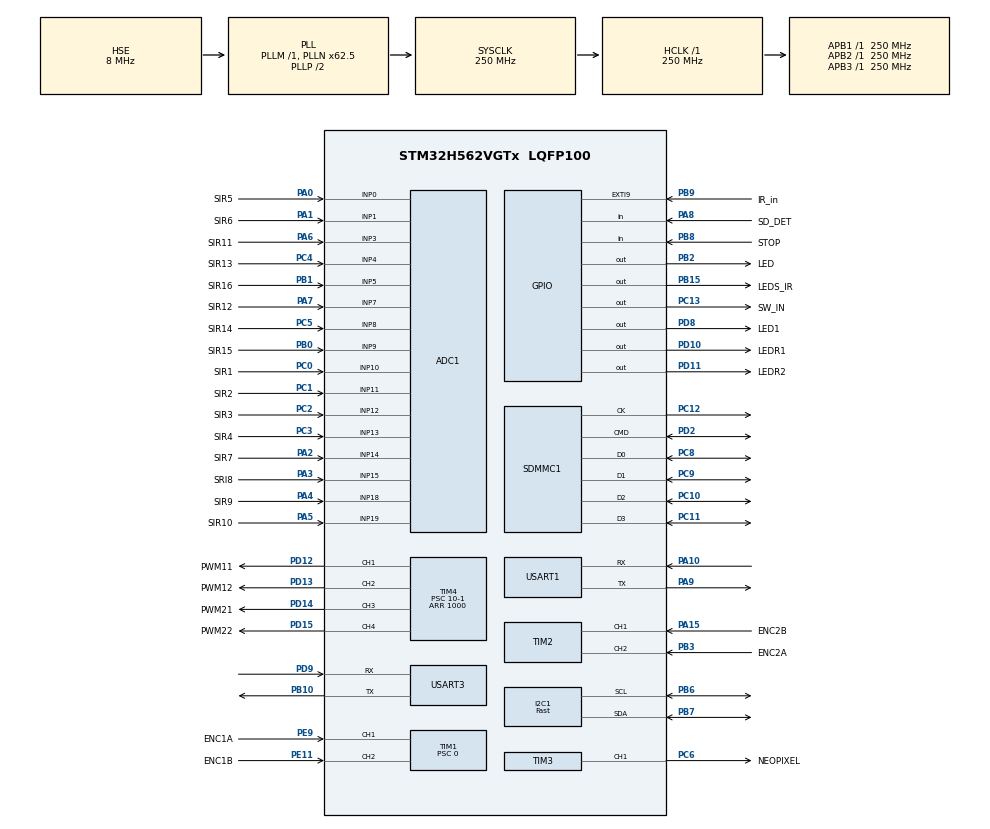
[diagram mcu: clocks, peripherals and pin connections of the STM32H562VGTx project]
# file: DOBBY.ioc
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ADC1.Channel-0\#ChannelRegularConversion=ADC_CHANNEL_10
ADC1.Channel-1\#ChannelRegularConversion=ADC_CHANNEL_11
ADC1.Channel-10\#ChannelRegularConversion=ADC_CHANNEL_3
ADC1.Channel-11\#ChannelRegularConversion=ADC_CHANNEL_7
ADC1.Channel-12\#ChannelRegularConversion=ADC_CHANNEL_4
ADC1.Channel-13\#ChannelRegularConversion=ADC_CHANNEL_8
ADC1.Channel-14\#ChannelRegularConversion=ADC_CHANNEL_9
ADC1.Channel-15\#ChannelRegularConversion=ADC_CHANNEL_5
ADC1.Channel-2\#ChannelRegularConversion=ADC_CHANNEL_12
ADC1.Channel-3\#ChannelRegularConversion=ADC_CHANNEL_13
ADC1.Channel-4\#ChannelRegularConversion=ADC_CHANNEL_0
ADC1.Channel-5\#ChannelRegularConversion=ADC_CHANNEL_1
ADC1.Channel-6\#ChannelRegularConversion=ADC_CHANNEL_15
ADC1.Channel-7\#ChannelRegularConversion=ADC_CHANNEL_14
ADC1.Channel-8\#ChannelRegularConversion=ADC_CHANNEL_18
ADC1.Channel-9\#ChannelRegularConversion=ADC_CHANNEL_19
ADC1.ClockPrescaler=ADC_CLOCK_ASYNC_DIV4
ADC1.ContinuousConvMode=ENABLE
ADC1.ConversionDataManagement=ADC_CONVERSIONDATA_DMA_CIRCULAR
ADC1.DMAContinuousRequests=ENABLE
ADC1.EOCSelection=ADC_EOC_SEQ_CONV
ADC1.MonitoredBy-0\#ChannelRegularConversion=__NULL
ADC1.MonitoredBy-1\#ChannelRegularConversion=__NULL
ADC1.MonitoredBy-10\#ChannelRegularConversion=__NULL
ADC1.MonitoredBy-11\#ChannelRegularConversion=__NULL
ADC1.MonitoredBy-12\#ChannelRegularConversion=__NULL
ADC1.MonitoredBy-13\#ChannelRegularConversion=__NULL
ADC1.MonitoredBy-14\#ChannelRegularConversion=__NULL
ADC1.MonitoredBy-15\#ChannelRegularConversion=__NULL
ADC1.MonitoredBy-2\#ChannelRegularConversion=__NULL
ADC1.MonitoredBy-3\#ChannelRegularConversion=__NULL
ADC1.MonitoredBy-4\#ChannelRegularConversion=__NULL
ADC1.MonitoredBy-5\#ChannelRegularConversion=__NULL
ADC1.MonitoredBy-6\#ChannelRegularConversion=__NULL
ADC1.MonitoredBy-7\#ChannelRegularConversion=__NULL
ADC1.MonitoredBy-8\#ChannelRegularConversion=__NULL
ADC1.MonitoredBy-9\#ChannelRegularConversion=__NULL
ADC1.NbrOfConversion=16
ADC1.NbrOfConversionFlag=1
ADC1.OffsetNumber-0\#ChannelRegularConversion=ADC_OFFSET_NONE
ADC1.OffsetNumber-1\#ChannelRegularConversion=ADC_OFFSET_NONE
ADC1.OffsetNumber-10\#ChannelRegularConversion=ADC_OFFSET_NONE
ADC1.OffsetNumber-11\#ChannelRegularConversion=ADC_OFFSET_NONE
ADC1.OffsetNumber-12\#ChannelRegularConversion=ADC_OFFSET_NONE
ADC1.OffsetNumber-13\#ChannelRegularConversion=ADC_OFFSET_NONE
ADC1.OffsetNumber-14\#ChannelRegularConversion=ADC_OFFSET_NONE
ADC1.OffsetNumber-15\#ChannelRegularConversion=ADC_OFFSET_NONE
ADC1.OffsetNumber-2\#ChannelRegularConversion=ADC_OFFSET_NONE
ADC1.OffsetNumber-3\#ChannelRegularConversion=ADC_OFFSET_NONE
ADC1.OffsetNumber-4\#ChannelRegularConversion=ADC_OFFSET_NONE
ADC1.OffsetNumber-5\#ChannelRegularConversion=ADC_OFFSET_NONE
ADC1.OffsetNumber-6\#ChannelRegularConversion=ADC_OFFSET_NONE
ADC1.OffsetNumber-7\#ChannelRegularConversion=ADC_OFFSET_NONE
ADC1.OffsetNumber-8\#ChannelRegularConversion=ADC_OFFSET_NONE
ADC1.OffsetNumber-9\#ChannelRegularConversion=ADC_OFFSET_NONE
ADC1.Rank-0\#ChannelRegularConversion=1
ADC1.Rank-1\#ChannelRegularConversion=2
ADC1.Rank-10\#ChannelRegularConversion=11
ADC1.Rank-11\#ChannelRegularConversion=12
ADC1.Rank-12\#ChannelRegularConversion=13
ADC1.Rank-13\#ChannelRegularConversion=14
ADC1.Rank-14\#ChannelRegularConversion=15
ADC1.Rank-15\#ChannelRegularConversion=16
ADC1.Rank-2\#ChannelRegularConversion=3
ADC1.Rank-3\#ChannelRegularConversion=4
ADC1.Rank-4\#ChannelRegularConversion=5
ADC1.Rank-5\#ChannelRegularConversion=6
ADC1.Rank-6\#ChannelRegularConversion=7
ADC1.Rank-7\#ChannelRegularConversion=8
ADC1.Rank-8\#ChannelRegularConversion=9
ADC1.Rank-9\#ChannelRegularConversion=10
ADC1.SamplingTime-0\#ChannelRegularConversion=ADC_SAMPLETIME_247CYCLES_5
ADC1.SamplingTime-1\#ChannelRegularConversion=ADC_SAMPLETIME_247CYCLES_5
ADC1.SamplingTime-10\#ChannelRegularConversion=ADC_SAMPLETIME_247CYCLES_5
ADC1.SamplingTime-11\#ChannelRegularConversion=ADC_SAMPLETIME_247CYCLES_5
ADC1.SamplingTime-12\#ChannelRegularConversion=ADC_SAMPLETIME_247CYCLES_5
ADC1.SamplingTime-13\#ChannelRegularConversion=ADC_SAMPLETIME_247CYCLES_5
ADC1.SamplingTime-14\#ChannelRegularConversion=ADC_SAMPLETIME_247CYCLES_5
ADC1.SamplingTime-15\#ChannelRegularConversion=ADC_SAMPLETIME_247CYCLES_5
ADC1.SamplingTime-2\#ChannelRegularConversion=ADC_SAMPLETIME_2CYCLES_5
ADC1.SamplingTime-3\#ChannelRegularConversion=ADC_SAMPLETIME_247CYCLES_5
ADC1.SamplingTime-4\#ChannelRegularConversion=ADC_SAMPLETIME_247CYCLES_5
ADC1.SamplingTime-5\#ChannelRegularConversion=ADC_SAMPLETIME_247CYCLES_5
ADC1.SamplingTime-6\#ChannelRegularConversion=ADC_SAMPLETIME_247CYCLES_5
ADC1.SamplingTime-7\#ChannelRegularConversion=ADC_SAMPLETIME_247CYCLES_5
ADC1.SamplingTime-8\#ChannelRegularConversion=ADC_SAMPLETIME_247CYCLES_5
ADC1.SamplingTime-9\#ChannelRegularConversion=ADC_SAMPLETIME_247CYCLES_5
ADC1.master=1
BOOTPATH.BootPathName=LEGACY
BOOTPATH.UserSelectedBootPath=LEGACY
CORTEX_M33_NS.Number-Cortex_Memory_Protection_Unit_Region0_OTP_RO_AREAS_Settings=MPU_REGION_NUMBER0
CORTEX_M33_NS.default_mode_Activation=1
CORTEX_M33_NS.userName=CORTEX_M33
GPDMA1.DESTDATAWIDTH_GPDMACH0=DMA_DEST_DATAWIDTH_BYTE
GPDMA1.DESTDATAWIDTH_GPDMACH1=DMA_DEST_DATAWIDTH_HALFWORD
GPDMA1.DESTINC_GPDMACH0=DMA_DINC_INCREMENTED
GPDMA1.DIRECTION_GPDMACH0=DMA_PERIPH_TO_MEMORY
GPDMA1.DIRECTION_GPDMACH1=DMA_MEMORY_TO_PERIPH
GPDMA1.IPHANDLE_GPDMACH0-SIMPLEREQUEST_GPDMACH0=__NULL
GPDMA1.IPHANDLE_GPDMACH1-SIMPLEREQUEST_GPDMACH1=__NULL
GPDMA1.PRIORITY_GPDMACH0=DMA_LOW_PRIORITY_HIGH_WEIGHT
GPDMA1.REQUEST_GPDMACH0=GPDMA1_REQUEST_USART1_RX
GPDMA1.REQUEST_GPDMACH1=GPDMA1_REQUEST_TIM3_CH1
GPDMA1.SRCDATAWIDTH_GPDMACH0=DMA_SRC_DATAWIDTH_BYTE
GPDMA1.SRCDATAWIDTH_GPDMACH1=DMA_SRC_DATAWIDTH_HALFWORD
GPDMA1.SRCINC_GPDMACH0=DMA_SINC_FIXED
GPDMA1.SRCINC_GPDMACH1=DMA_SINC_INCREMENTED
GPDMA2.CIRCULARMODE_GPDMACH0=ENABLE
GPDMA2.DESTDATAWIDTH_GPDMACH0=DMA_DEST_DATAWIDTH_HALFWORD
GPDMA2.DESTINC_GPDMACH0=DMA_DINC_INCREMENTED
GPDMA2.IPHANDLE_GPDMACH0-SIMPLEREQUEST_GPDMACH0=__NULL
GPDMA2.PRIORITY_LL_CIRCULAR_GPDMACH0=DMA_HIGH_PRIORITY
GPDMA2.REQUEST_GPDMACH0=GPDMA2_REQUEST_ADC1
GPDMA2.SRCDATAWIDTH_GPDMACH0=DMA_SRC_DATAWIDTH_HALFWORD
I2C1.I2C_Speed_Mode=I2C_Fast
I2C1.Timing=0x10C043E5
Mcu.Family=STM32H5
Mcu.Name=STM32H562VGTx
Mcu.Package=LQFP100
NVIC.EXTI9_IRQn=true\:0\:0\:true\:false\:true\:true\:true\:true
NVIC.GPDMA1_Channel0_IRQn=true\:0\:0\:false\:false\:true\:false\:true\:true
NVIC.GPDMA1_Channel1_IRQn=true\:0\:0\:false\:false\:true\:false\:true\:true
NVIC.GPDMA2_Channel0_IRQn=true\:0\:0\:false\:false\:true\:false\:true\:true
NVIC.PriorityGroup=NVIC_PRIORITYGROUP_4
NVIC.TIM6_IRQn=true\:1\:0\:true\:false\:true\:true\:true\:true
NVIC.TIM7_IRQn=true\:2\:0\:true\:false\:true\:true\:true\:true
NVIC.USART1_IRQn=true\:1\:0\:true\:false\:true\:true\:true\:true
PA0.GPIO_Label=SIR5
PA0.Signal=ADCx_INP0
PA1.GPIO_Label=SIR6
PA1.Signal=ADCx_INP1
PA10.Mode=Asynchronous
PA10.Signal=USART1_RX
PA15(JTDI).GPIO_Label=ENC2B
PA15(JTDI).Signal=S_TIM2_CH1
PA2.GPIO_Label=SIR7
PA2.Signal=ADCx_INP14
PA3.GPIO_Label=SRI8
PA3.Signal=ADCx_INP15
PA4.GPIO_Label=SIR9
PA4.Signal=ADCx_INP18
PA5.GPIO_Label=SIR10
PA5.Signal=ADCx_INP19
PA6.GPIO_Label=SIR11
PA6.Signal=ADCx_INP3
PA7.GPIO_Label=SIR12
PA7.Signal=ADCx_INP7
PA8.GPIO_Label=SD_DET
PA8.GPIO_PuPd=GPIO_PULLUP
PA8.Signal=GPIO_Input
PA9.Mode=Asynchronous
PA9.Signal=USART1_TX
PB0.GPIO_Label=SIR15
PB0.Signal=ADCx_INP9
PB1.GPIO_Label=SIR16
PB1.Signal=ADCx_INP5
PB10.Mode=Asynchronous
PB10.Signal=USART3_TX
PB15.GPIO_Label=LEDS_IR
PB15.Signal=GPIO_Output
PB2.GPIO_Label=LED
PB2.Signal=GPIO_Output
PB3(JTDO/TRACESWO).GPIO_Label=ENC2A
PB3(JTDO/TRACESWO).Signal=S_TIM2_CH2
PB6.Mode=I2C
PB6.Signal=I2C1_SCL
PB7.Mode=I2C
PB7.Signal=I2C1_SDA
PB8.GPIO_Label=STOP
PB8.Signal=GPIO_Input
PB9.GPIO_Label=IR_in
PB9.GPIO_PuPd=GPIO_PULLUP
PB9.Signal=GPXTI9
PC0.GPIO_Label=SIR1
PC0.Signal=ADCx_INP10
PC1.GPIO_Label=SIR2
PC1.Signal=ADCx_INP11
PC10.GPIO_Speed_Default_HIGH=GPIO_SPEED_FREQ_VERY_HIGH
PC10.Mode=SD_4_bits_Wide_bus
PC10.Signal=SDMMC1_D2
PC11.GPIO_Speed_Default_HIGH=GPIO_SPEED_FREQ_VERY_HIGH
PC11.Mode=SD_4_bits_Wide_bus
PC11.Signal=SDMMC1_D3
PC12.GPIO_Speed_Default_HIGH=GPIO_SPEED_FREQ_VERY_HIGH
PC12.Mode=SD_4_bits_Wide_bus
PC12.Signal=SDMMC1_CK
PC13.GPIO_Label=SW_IN
PC13.Signal=GPIO_Output
PC14-OSC32_IN(OSC32_IN).Mode=LSE-External-Oscillator
PC14-OSC32_IN(OSC32_IN).Signal=RCC_OSC32_IN
PC15-OSC32_OUT(OSC32_OUT).Mode=LSE-External-Oscillator
PC15-OSC32_OUT(OSC32_OUT).Signal=RCC_OSC32_OUT
PC2.GPIO_Label=SIR3
PC2.Signal=ADCx_INP12
PC3.GPIO_Label=SIR4
PC3.Signal=ADCx_INP13
PC4.GPIO_Label=SIR13
PC4.Signal=ADCx_INP4
PC5.GPIO_Label=SIR14
PC5.Signal=ADCx_INP8
PC6.GPIO_Label=NEOPIXEL
PC6.Signal=S_TIM3_CH1
PC8.GPIO_Speed_Default_HIGH=GPIO_SPEED_FREQ_VERY_HIGH
PC8.Mode=SD_4_bits_Wide_bus
PC8.Signal=SDMMC1_D0
PC9.Mode=SD_4_bits_Wide_bus
PC9.Signal=SDMMC1_D1
PD10.GPIO_Label=LEDR1
PD10.Signal=GPIO_Output
PD11.GPIO_Label=LEDR2
PD11.Signal=GPIO_Output
PD12.GPIO_Label=PWM11
PD12.Signal=S_TIM4_CH1
PD13.GPIO_Label=PWM12
PD13.Signal=S_TIM4_CH2
PD14.GPIO_Label=PWM21
PD14.Signal=S_TIM4_CH3
PD15.GPIO_Label=PWM22
PD15.Signal=S_TIM4_CH4
PD2.GPIO_Speed_Default_HIGH=GPIO_SPEED_FREQ_VERY_HIGH
PD2.Mode=SD_4_bits_Wide_bus
PD2.Signal=SDMMC1_CMD
PD8.GPIO_Label=LED1
PD8.Signal=GPIO_Output
PD9.Mode=Asynchronous
PD9.Signal=USART3_RX
PE11.GPIO_Label=ENC1B
PE11.Signal=S_TIM1_CH2
PE9.GPIO_Label=ENC1A
PE9.Signal=S_TIM1_CH1
PH0-OSC_IN(PH0).Mode=HSE-External-Oscillator
PH0-OSC_IN(PH0).Signal=RCC_OSC_IN
PH1-OSC_OUT(PH1).Mode=HSE-External-Oscillator
PH1-OSC_OUT(PH1).Signal=RCC_OSC_OUT
ProjectManager.HeapSize=0x1000
ProjectManager.StackSize=0x4000
ProjectManager.TargetToolchain=CMake
RCC.ADCFreq_Value=250000000
RCC.AHBFreq_Value=250000000
RCC.APB1Freq_Value=250000000
RCC.APB1TimFreq_Value=250000000
RCC.APB2Freq_Value=250000000
RCC.APB2TimFreq_Value=250000000
RCC.APB3Freq_Value=250000000
RCC.CSI_VALUE=4000000
RCC.CortexFreq_Value=250000000
RCC.EPOD_VALUE=8000000
RCC.HCLKFreq_Value=250000000
RCC.HSE_VALUE=8000000
RCC.HSI48_VALUE=48000000
RCC.HSI_VALUE=64000000
RCC.LSIRC_VALUE=32000
RCC.PLLFRACN=4096
RCC.PLLN=62
RCC.PLLSourceVirtual=RCC_PLL1_SOURCE_HSE
RCC.SYSCLKFreq_VALUE=250000000
RCC.SYSCLKSource=RCC_SYSCLKSOURCE_PLLCLK
RCC.USBFreq_Value=48000000
RCC.VCOOutputFreq_Value=500000000
SDMMC1.ClockDiv=8
SH.ADCx_INP0.0=ADC1_INP0,IN0-Single-Ended
SH.ADCx_INP1.0=ADC1_INP1,IN1-Single-Ended
SH.ADCx_INP10.0=ADC1_INP10,IN10-Single-Ended
SH.ADCx_INP11.0=ADC1_INP11,IN11-Single-Ended
SH.ADCx_INP12.0=ADC1_INP12,IN12-Single-Ended
SH.ADCx_INP13.0=ADC1_INP13,IN13-Single-Ended
SH.ADCx_INP14.0=ADC1_INP14,IN14-Single-Ended
SH.ADCx_INP15.0=ADC1_INP15,IN15-Single-Ended
SH.ADCx_INP18.0=ADC1_INP18,IN18-Single-Ended
SH.ADCx_INP19.0=ADC1_INP19,IN19-Single-Ended
SH.ADCx_INP3.0=ADC1_INP3,IN3-Single-Ended
SH.ADCx_INP4.0=ADC1_INP4,IN4-Single-Ended
SH.ADCx_INP5.0=ADC1_INP5,IN5-Single-Ended
SH.ADCx_INP7.0=ADC1_INP7,IN7-Single-Ended
SH.ADCx_INP8.0=ADC1_INP8,IN8-Single-Ended
SH.ADCx_INP9.0=ADC1_INP9,IN9-Single-Ended
SH.S_TIM1_CH1.0=TIM1_CH1,Encoder_Interface
SH.S_TIM1_CH2.0=TIM1_CH2,Encoder_Interface
SH.S_TIM2_CH1.0=TIM2_CH1,Encoder_Interface
SH.S_TIM2_CH2.0=TIM2_CH2,Encoder_Interface
SH.S_TIM3_CH1.0=TIM3_CH1,PWM Generation1 CH1
SH.S_TIM4_CH1.0=TIM4_CH1,PWM Generation1 CH1
SH.S_TIM4_CH2.0=TIM4_CH2,PWM Generation2 CH2
SH.S_TIM4_CH3.0=TIM4_CH3,PWM Generation3 CH3
SH.S_TIM4_CH4.0=TIM4_CH4,PWM Generation4 CH4
TIM1.AutoReloadPreload=TIM_AUTORELOAD_PRELOAD_DISABLE
TIM1.PeriodNoDither=65535
TIM1.Prescaler=0
TIM3.AutoReloadPreload=TIM_AUTORELOAD_PRELOAD_ENABLE
TIM3.Channel-PWM\ Generation1\ CH1=TIM_CHANNEL_1
TIM3.PeriodNoDither=312
TIM3.PulseNoDither_1=99
TIM4.AutoReloadPreload=TIM_AUTORELOAD_PRELOAD_ENABLE
TIM4.Channel-PWM\ Generation1\ CH1=TIM_CHANNEL_1
TIM4.Channel-PWM\ Generation2\ CH2=TIM_CHANNEL_2
TIM4.Channel-PWM\ Generation3\ CH3=TIM_CHANNEL_3
TIM4.Channel-PWM\ Generation4\ CH4=TIM_CHANNEL_4
TIM4.PeriodNoDither=1000
TIM4.Prescaler=10-1
TIM6.AutoReloadPreload=TIM_AUTORELOAD_PRELOAD_ENABLE
TIM6.PeriodNoDither=500-1
TIM6.Prescaler=2500-1
TIM7.AutoReloadPreload=TIM_AUTORELOAD_PRELOAD_ENABLE
TIM7.PeriodNoDither=8000
TIM7.Prescaler=250-1
USART1.VirtualMode-Asynchronous=VM_ASYNC
USART3.VirtualMode-Asynchronous=VM_ASYNC
VP_BOOTPATH_VS_BOOTPATH.Mode=BP_Activate
VP_CORTEX_M33_NS_VS_Hclk.Mode=Hclk_Mode
VP_GPDMA1_VS_GPDMACH0.Mode=SIMPLEREQUEST_GPDMACH0
VP_GPDMA1_VS_GPDMACH1.Mode=SIMPLEREQUEST_GPDMACH1
VP_GPDMA2_VS_GPDMACH0.Mode=SIMPLEREQUEST_GPDMACH0
VP_ICACHE_VS_ICACHE.Mode=DirectMappedCache
VP_MEMORYMAP_VS_MEMORYMAP.Mode=CurAppReg
VP_PWR_VS_LPOM.Mode=PowerOptimisation
VP_PWR_VS_SECSignals.Mode=Security/Privilege
VP_TIM3_VS_ClockSourceINT.Mode=Internal
VP_TIM4_VS_ClockSourceINT.Mode=Internal
VP_TIM6_VS_ClockSourceINT.Mode=Enable_Timer
VP_TIM7_VS_ClockSourceINT.Mode=Enable_Timer
board=custom

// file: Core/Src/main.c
/* USER CODE BEGIN Header */
/**
  ******************************************************************************
  * @file           : main.c
  * @brief          : Main program body
  ******************************************************************************
  * @attention
  *
  * Copyright (c) 2026 STMicroelectronics.
  * All rights reserved.
  *
  * This software is licensed under terms that can be found in the LICENSE file
  * in the root directory of this software component.
  * If no LICENSE file comes with this software, it is provided AS-IS.
  *
  ******************************************************************************
  */
/* USER CODE END Header */
#include "main.h"

/* USER CODE BEGIN Includes */
#include "stdio.h"
#include "stdlib.h"
#include "string.h"
#include "math.h"
#include "stdbool.h"
#include "stdint.h"

#include "pinout1.h"
#include "bits.h"
#include "uart.h"
#include "UARTRX.h"
#include "adc_x.h"
#include "ws2812b.h"
#include "delays.h"
#include "DRV8871.h"
#include "IR_ANA_SEN.h"
#include "PWMB.h"
#include "MPU6050.h"
#include "kalman.h"
#include "timer.h"
#include "I2C_SCAN_BUS.h"
#include "encoder.h"
#include "llanta.h"
#include "parametros.h"
#include "sd_card.h"
#include "ircodigo.h"
#include "PID.h"
#include "telemetria.h"
#include "pruebas.h"
#include "carrera.h"
#include "pista_mapa.h"
/* USER CODE END Includes */

ADC_HandleTypeDef hadc1;
DMA_NodeTypeDef Node_GPDMA2_Channel0;
DMA_QListTypeDef List_GPDMA2_Channel0;
DMA_HandleTypeDef handle_GPDMA2_Channel0;

I2C_HandleTypeDef hi2c1;

SD_HandleTypeDef hsd1;

TIM_HandleTypeDef htim1;
TIM_HandleTypeDef htim2;
TIM_HandleTypeDef htim3;
TIM_HandleTypeDef htim4;
TIM_HandleTypeDef htim6;
TIM_HandleTypeDef htim7;
DMA_HandleTypeDef handle_GPDMA1_Channel1;

UART_HandleTypeDef huart1;
UART_HandleTypeDef huart3;
DMA_HandleTypeDef handle_GPDMA1_Channel0;

/* USER CODE BEGIN PV */
char procesa[100];
uint32_t milis_pixel=0;
uint32_t milis_musica=0;
uint32_t milis_pid=0;

enum pixel_m_estado {apagado,rojo,verde, azul,rosado,morado,blanco,amarillo};
uint8_t  estado_pixel=apagado;
#define retardo_pixe 50
#define retardo_musica 55000
char texto[600];
float pesos_ARZ;

//variables para iniciar o pearr el robot
uint8_t R_START=0;
uint8_t R_STOP=0;
uint8_t  PID_VAR=0;
uint8_t cancion=1;
int8_t volumen=25;
extern uint8_t flag_fuera;

uint32_t recta=7500;
uint32_t  recta_inicio=0;
uint8_t flag_recta=0;
uint32_t recta_velo=12000;

//flag_text ya no se usa: la bandera de TEST es PRUEBA.activo (pruebas.h)
uint8_t  luces=0;     //LUZ=n/: 0 = apagadas, 1..6 = color de LUZ_COLOR
uint8_t  play=0;      //musica sonando (falta la libreria mp3)
//codigos ir (IRSTART, IRSTOP...): ver ircodigo.h

//ADC
uint16_t codigo;
float voltaje;
float bateria;

float  sd_kp,sd_ki,sd_kd,sd_tau,sd_kaw,velo_giro;

/* USER CODE END PV */

void SystemClock_Config(void);
static void MPU_Config(void);
static void MX_GPIO_Init(void);
static void MX_GPDMA1_Init(void);
static void MX_GPDMA2_Init(void);
static void MX_ADC1_Init(void);
static void MX_I2C1_Init(void);
static void MX_ICACHE_Init(void);
static void MX_TIM1_Init(void);
static void MX_TIM2_Init(void);
static void MX_TIM3_Init(void);
static void MX_TIM4_Init(void);
static void MX_USART3_UART_Init(void);
static void MX_USART1_UART_Init(void);
static void MX_TIM6_Init(void);
static void MX_SDMMC1_SD_Init(void);
static void MX_TIM7_Init(void);

/* USER CODE BEGIN 0 */
void lee_ir()
{
	uint32_t codigo_ir;
	if (IR_leer(&codigo_ir))   //1 = llego un codigo (ya queda rearmado)
	{
     PIN_BLINK(LED);
	sprintf(texto,"codigo=0x%08lX/\r\n",(unsigned long)codigo_ir);
	uartx_write_text(&huart1, texto);
	if ((codigo_ir==IRSTART)||(codigo_ir==IRSTART2))
		{
		 uartx_write_text(&huart1, "START\r\n");
       R_START=1;
       R_STOP=0;
       Carrera_run();          //REPOSO -> PID
       //Analizar si debo colocar la rampa de arranque.
   //    if (rampamot==1)   Motores_Arranque();//aplico rampa de arranque

//		WS2812_Color(0, 255,0 );
		   WS2812_Color(0, 0,0 );

       WS2812_Manda_Trama();
		}
	  if ((codigo_ir==IRSTOP) ||(codigo_ir==IRSTOP2))
		  {
		 uartx_write_text(&huart1, "STOP\r\n");
		  R_STOP=1;
		  R_START=0;
		  Carrera_stop();       //-> REPOSO frenando
		  WS2812_Color(255, 0,0 );
		  	WS2812_Manda_Trama();

		  }

	  if ((codigo_ir==IRPROG))
	  		  {
	  		 uartx_write_text(&huart1, "PROG1\r\n");
	  	//	 mp3_modo_play();
	  	//	 mp3_next();

	  		  }

	  if ((codigo_ir==IRPROG2))
	  		  {
	  		 uartx_write_text(&huart1, "PROG2\r\n");
	  	//	  mp3_modo_pausa();

	  		  }

	}

}

//=============================================================================
//                   COMANDOS DEL PANEL (dobby_panel.py / celular)
//=============================================================================
#define USA_MP3   0     //1 cuando se agregue la libreria mp3 (mp3_next, mp3_play_x ...)

static uint8_t  aviso = 0;
static uint32_t t_aviso = 0;

//colores del boton Luces,
#define LUZ_N_COLORES 6
static const uint8_t LUZ_COLOR[LUZ_N_COLORES][3] = {
  {255,   0,   0},   //1 rojo
  {  0, 255,   0},   //2 verde
  {  0,   0, 255},   //3 azul
  {255, 180,   0},   //4 amarillo
  {128,   0, 255},   //5 morado
  {255, 255, 255},   //6 blanco
};

//color de fondo del WS2812 segun el estado del robot
static void Color_base(void)
{
  if (PRUEBA.activo) WS2812_Color(80, 60, 0);       //amarillo: TEST
  else if (luces)    WS2812_Color(LUZ_COLOR[luces - 1][0], LUZ_COLOR[luces - 1][1], LUZ_COLOR[luces - 1][2]);
  else               WS2812_Color(0, 0, 0);
  WS2812_Manda_Trama();
}

//parpadeo magenta: llego un comando (se apaga solo en Aviso_tarea)
static void Aviso_on(void)
{
  WS2812_Color(255, 0, 255);
  WS2812_Manda_Trama();
  aviso = 1;
  t_aviso = HAL_GetTick();
}

//en el while: termina el parpadeo a los 80 ms
void Aviso_tarea(void)
{
  if (aviso && (HAL_GetTick() - t_aviso >= 80))
  {
    aviso = 0;
    Color_base();
  }
}

//busca "clave" en la trama y lee el numero que sigue (ej. "PROPOR=50.0/" -> 50.0)
static uint8_t lee_num(const char *trama, const char *clave, float *valor)
{
  const char *p = strstr(trama, clave);
  if (p == 0) return 0;
  *valor = strtof(p + strlen(clave), 0);
  return 1;
}

//robot detenido: se puede grabar flash, calibrar sensores...
static uint8_t Robot_quieto(void)
{
  return (CARRERA.estado == CARRERA_REPOSO) && (LLANTA_CAL.modo == LLANTA_OFF);
}

//procesa UN comando (copia de UARTRX1.trama_rx; la recepcion ya esta rearmada)
//ORDEN: primero las librerias, despues los comandos generales.
//OJO con strstr: "TAU=" tambien esta dentro de "VTAU=" -> los V... los toma antes Llanta_comando
void procesa_rx(char *trama)
{
  float v;
  uint8_t pid_dir = 0;    //1 = cambio el PID de linea: aplicar y avisar al panel

  Aviso_on();

  //---------------- 1) TEST: TESTON, TESTOFF, TESTSEL=, PWMIZQ=, PWMDER=
  if (Prueba_comando(trama)) return;

  //---------------- 2) STOP general (antes que Llanta_comando, que tambien lo toma)
  if (strstr(trama, "STOP"))
  {
    R_START = 0;
    R_STOP  = 0;
    Pista_mapa_cancelar();    // STOP invalida una grabacion incompleta
    Carrera_stop();          //-> REPOSO: apaga PID, test y frena
    return;
  }

  //---------------- V5: aprendizaje generico de una vuelta en RAM.
  // No usa las ordenes RUN/STOP para activar mapa accidentalmente.
  if (strstr(trama, "MAPBEGIN"))
  {
    if (!Robot_quieto())
    {
      uartx_write_text(&huart1, "MAPA: primero detener el robot\r\n");
      return;
    }
    if (Pista_mapa_iniciar(ROBOT.distancia))
    {
      uartx_write_text(&huart1, "MAPA: aprendiendo, marque FIN al completar una vuelta\r\n");
      Carrera_run(); // el control sigue siendo V3, sin velocidad anticipativa
    }
    return;
  }

  if (strstr(trama, "MAPEND"))
  {
    if (Pista_mapa_estado() != PISTA_APRENDIENDO)
    {
      // FIN VUELTA siempre detiene el robot, incluso si se lleno la RAM.
      Carrera_stop();
      uartx_write_text(&huart1, "MAPA: no hay aprendizaje activo / memoria llena\r\n");
      Pista_mapa_estado_uart();
      return;
    }
    uint8_t completo = Pista_mapa_finalizar(ROBOT.distancia);
    Carrera_stop();
    if (completo)
    {
      // El mapa ya esta congelado. Grabacion Flash exclusivamente desde main,
      // con motores detenidos y nunca desde TIM6 ni interrupciones.
      HAL_Delay(150);
      uartx_write_text(&huart1, Pista_mapa_guardar_flash() ?
                       "MAPA FLASH: GUARDADO OK + CRC; persiste al apagar\r\n" :
                       "MAPA FLASH: ERROR DE GUARDADO; mapa solo en RAM\r\n");
    }
    else
      uartx_write_text(&huart1, "MAPA: vuelta incompleta (<1 m o <50 puntos)\r\n");
    Pista_mapa_estado_uart();
    return;
  }

  if (strstr(trama, "MAPSTATUS"))
  {
    Pista_mapa_estado_uart();
    return;
  }

  // Para comprobacion y recuperacion manual. El mapa normal se guarda
  // automaticamente con FIN VUELTA y se carga al encender.
  if (strstr(trama, "MAPSAVE"))
  {
    if (!Robot_quieto())
      uartx_write_text(&huart1, "MAPA FLASH: detenga el robot antes de guardar\r\n");
    else
      uartx_write_text(&huart1, Pista_mapa_guardar_flash() ?
                       "MAPA FLASH: GUARDADO OK + CRC\r\n" :
                       "MAPA FLASH: error / mapa no valido\r\n");
    Pista_mapa_estado_uart();
    return;
  }
  if (strstr(trama, "MAPLOAD"))
  {
    if (!Robot_quieto())
      uartx_write_text(&huart1, "MAPA FLASH: detenga el robot antes de cargar\r\n");
    else
      uartx_write_text(&huart1, Pista_mapa_leer_flash() ?
                       "MAPA FLASH: CARGADO OK desde Flash\r\n" :
                       "MAPA FLASH: no hay mapa con CRC valido\r\n");
    Pista_mapa_estado_uart();
    return;
  }

  // Replay mapado: la referencia fisica de salida se mantiene por el operador.
  if (strstr(trama, "MAPRUN"))
  {
    if (!Robot_quieto())
    {
      uartx_write_text(&huart1, "MAPA: primero detener el robot\r\n");
      return;
    }
    uint8_t perfil = strstr(trama, "MAPRUNFAST") ? PISTA_PERFIL_RAPIDO :
                                                  PISTA_PERFIL_SEGURO;
    if (!Pista_mapa_replay_iniciar(ROBOT.distancia, perfil))
    {
      uartx_write_text(&huart1, "MAPA: no valido o incompleto; haga APRENDER\r\n");
      Pista_mapa_estado_uart();
      return;
    }
    uartx_write_text(&huart1, perfil == PISTA_PERFIL_RAPIDO ?
                      "MAPA: carrera RAPIDA iniciada\r\n" :
                      "MAPA: carrera SEGURA iniciada\r\n");
    Carrera_run();
    return;
  }

  //---------------- 3) PID de velocidad: VKP= VKI= VKD= VTAU= VKAW= VIZQ= VDER= VPID= VESC= VIDENT=
  if (Llanta_comando(trama)) return;

  //---------------- 4) carrera
  if (strstr(trama, "RUN"))
  {
    R_START = 1;
    R_STOP  = 0;
    Carrera_run();           //REPOSO -> PID (sigue la linea, ver carrera.h)
    return;
  }

  //---------------- 5) parametros, SD y flash
  if (strstr(trama, "PIDVAL"))   { manda_pid_parametros(); return; }

  if (strstr(trama, "DAT/"))     //trama completa de parametros (ver parametros.h)
  {
    if (Param_desde_trama(trama)) { Param_aplica(); manda_pid_parametros(); }
    else uartx_write_text(&huart1, "DAT: trama incompleta\r\n");
    return;
  }

  if (strstr(trama, "GUARDASD"))  //guarda PARAM en la SD (datos.txt) y en la flash
  {
    Param_a_trama(texto);
    uartx_write_text(&huart1, SD_WRITE_TEXT(file_name, texto) ? "SD: guardado\r\n"
                                                               : "SD: error al guardar\r\n");
    if (Robot_quieto())
      uartx_write_text(&huart1, Param_guardar() ? "FLASH: guardado\r\n" : "FLASH: error\r\n");
    else
      uartx_write_text(&huart1, "FLASH: no se graba con el robot andando\r\n");
    return;
  }

  if (strstr(trama, "LEESD"))     //lee PARAM de la SD y lo aplica
  {
    if (SD_READ_LINE_N(file_name, 0) && Param_desde_trama(SD_BUFFER))
    {
      Param_aplica();
      uartx_write_text(&huart1, "SD: parametros leidos\r\n");
      manda_pid_parametros();
    }
    else uartx_write_text(&huart1, "SD: no se pudo leer los parametros\r\n");
    return;
  }

  if (strstr(trama, "LEEFLASH"))  //lee PARAM de la flash y lo aplica
  {
    if (Param_leer_flash())
    {
      Param_aplica();
      uartx_write_text(&huart1, "FLASH: parametros leidos\r\n");
      manda_pid_parametros();
    }
    else uartx_write_text(&huart1, "FLASH: no hay parametros guardados\r\n");
    return;
  }

  if (strstr(trama, "CALI"))      //calibra los sensores de linea
  {
    if (!Robot_quieto()) { uartx_write_text(&huart1, "CALI: detener el robot\r\n"); return; }
    Calibrar_sensores();
    Manda_Limites();
    return;
  }

  //---------------- 6) luces
  if (lee_num(trama, "LUZ=", &v))                       //Aviso_tarea pone el color
  {
    luces = ((v >= 1.0f) && (v <= (float)LUZ_N_COLORES)) ? (uint8_t)v : 0;   //fuera de rango: apaga
    return;
  }

  //---------------- 7) PID de linea (PARAM -> Param_aplica)
  if      (strstr(trama, "KP+")) { PARAM.kp += 1.0f;  pid_dir = 1; }
  else if (strstr(trama, "KP-")) { PARAM.kp -= 1.0f;  pid_dir = 1; }
  else if (strstr(trama, "KI+")) { PARAM.ki += 0.01f; pid_dir = 1; }
  else if (strstr(trama, "KI-")) { PARAM.ki -= 0.01f; pid_dir = 1; }
  else if (strstr(trama, "KD+")) { PARAM.kd += 0.1f;  pid_dir = 1; }
  else if (strstr(trama, "KD-")) { PARAM.kd -= 0.1f;  pid_dir = 1; }
  else if (lee_num(trama, "PROPOR=",  &v)) { PARAM.kp  = v; pid_dir = 1; }
  else if (lee_num(trama, "INTEGRA=", &v)) { PARAM.ki  = v; pid_dir = 1; }
  else if (lee_num(trama, "DERIVA=",  &v)) { PARAM.kd  = v; pid_dir = 1; }
  else if (lee_num(trama, "TAU=",     &v)) { PARAM.tau = v; pid_dir = 1; }   //en multiplos de Ts
  else if (lee_num(trama, "KAW=",     &v)) { PARAM.kaw = v; pid_dir = 1; }   //factor de Ki/Kp
  else if (lee_num(trama, "VGIRO=",   &v)) { PARAM.vel_giro = v; pid_dir = 1; }
  else if (lee_num(trama, "KGIRO=",   &v)) { PARAM.kg = v;       pid_dir = 1; }
  else if (lee_num(trama, "VBASICA=", &v)) { PARAM.velo_basica = v; pid_dir = 1; }
  else if (strstr(trama, "VC+"))           { PARAM.velo_basica += 1.0f; pid_dir = 1; }
  else if (strstr(trama, "VC-"))           { PARAM.velo_basica -= 1.0f; pid_dir = 1; }

  //rectas (carrera.c, estado RECTA)
  else if (lee_num(trama, "RECTERR=",  &v)) { PARAM.error_recta = v; pid_dir = 1; }   //Error_LIM (posicion)
  else if (lee_num(trama, "RECTGIR=",  &v)) { PARAM.giro_recta  = v; pid_dir = 1; }   //GIRO_LIM (grados/s)
  else if (lee_num(trama, "RECTVEL=",  &v)) { PARAM.velo_recta  = v; pid_dir = 1; }   //V_LINEA (PWM)
  else if (lee_num(trama, "RECTLARG=", &v)) { PARAM.largo_recta = v; pid_dir = 1; }   //TRAMO (cm)
  else if (lee_num(trama, "ACELR=",    &v)) { PARAM.acel_recta  = v; pid_dir = 1; }   //ACEL_R (PWM/s)

  //freno al salir de la recta (carrera.c, estado FRENO)
  else if (lee_num(trama, "FRENOV=",  &v)) { PARAM.velo_freno = v; pid_dir = 1; }     //V_FRENO (PWM)
  else if (lee_num(trama, "FRENOMS=", &v)) { PARAM.freno_ms   = v; pid_dir = 1; }     //T_FRENO (ms)

  //color de linea: 0 = blanca, 1 = negra (IR_ANA_SEN.h)
  else if (lee_num(trama, "LINCO=", &v))    { PARAM.linea_color = (v > 0.5f) ? 1 : 0; pid_dir = 1; }

  if (pid_dir)
  {
    Param_aplica();          //PID_Sintoniza + limites + color: los cambios SI tienen efecto
    manda_pid_parametros();  //el panel ve en rojo los valores que quedaron
    return;
  }

  //---------------- 8) ajuste de la velocidad de cada llanta (m/s) desde el celular
  if (strstr(trama, "VD+") || strstr(trama, "VD-") || strstr(trama, "VI+") || strstr(trama, "VI-"))
  {
    if      (strstr(trama, "VD+")) LLANTA_DER.vref += 0.1f;
    else if (strstr(trama, "VD-")) LLANTA_DER.vref -= 0.1f;
    else if (strstr(trama, "VI+")) LLANTA_IZQ.vref += 0.1f;
    else                           LLANTA_IZQ.vref -= 0.1f;
    sprintf(texto, "*x%.2f**y%.2f*", LLANTA_DER.vref, LLANTA_IZQ.vref);
    uartx_write_text(&huart1, texto);
    return;
  }

  //---------------- 9) musica
  if (strstr(trama, "NEXT") || strstr(trama, "PREV") || strstr(trama, "PLAY") ||
      strstr(trama, "SILE") || strstr(trama, "V+")   || strstr(trama, "V-")   ||
      strstr(trama, "SUENA="))
  {
#if USA_MP3
    if      (strstr(trama, "NEXT")) { if (play) mp3_next(); }
    else if (strstr(trama, "PREV")) { if (play) mp3_previo(); }
    else if (strstr(trama, "PLAY")) { play = 1; mp3_modo_play(); mp3_next(); }
    else if (strstr(trama, "SILE")) { play = 0; mp3_modo_reset(); }
    else if (strstr(trama, "V+"))   { if (++volumen > 30) volumen = 30; if (play) mp3_volumen_x(volumen); }
    else if (strstr(trama, "V-"))   { if (--volumen < 0)  volumen = 0;  if (play) mp3_volumen_x(volumen); }
    else if (lee_num(trama, "SUENA=", &v)) mp3_play_x((uint8_t)v);
#else
    uartx_write_text(&huart1, "MP3: falta la libreria (USA_MP3 = 0)\r\n");
#endif
    return;
  }

  //comando desconocido: eco para verlo en TRAMA
  uartx_write_text(&huart1, trama);
  uartx_write_text(&huart1, "\r\n");
}

//robot QUIETO: cada 200 ms manda posicion de la linea, giro y velocidades
//(en carrera, cuando exista el lazo, usar manda_operando)
void Tarea_espera(void)
{
  static uint32_t t = 0;
  if (CARRERA.estado != CARRERA_REPOSO) return;   //en carrera manda Carrera_tarea
  if (HAL_GetTick() - t < 200) return;
  t = HAL_GetTick();

  Lee_sensores();
  filtra_sensores();
  Normaliza_sensores();
  Calcula_Pesos();          //deja la posicion en 'peso'
  manda_espera_start();
  Manda_Normalizados();     //Nor=... -> LEDs I8..D8 del panel (ver que sensores sirven)
  manda_crudos();           //Cru=... -> numero crudo del ADC debajo de cada LED
}

/* USER CODE END 0 */

int main(void)
{

  /* MCU Configuration--------------------------------------------------------*/

  /* MPU Configuration--------------------------------------------------------*/
  MPU_Config();

  /* Reset of all peripherals, Initializes the Flash interface and the Systick. */
  HAL_Init();

  /* Configure the system clock */
  SystemClock_Config();

  /* Initialize all configured peripherals */
  MX_GPIO_Init();
  MX_GPDMA1_Init();
  MX_GPDMA2_Init();
  MX_ADC1_Init();
  MX_I2C1_Init();
  MX_ICACHE_Init();
  MX_TIM1_Init();
  MX_TIM2_Init();
  MX_TIM3_Init();
  MX_TIM4_Init();
  MX_USART3_UART_Init();
  MX_USART1_UART_Init();
  MX_TIM6_Init();
  MX_SDMMC1_SD_Init();
  MX_TIM7_Init();
  /* USER CODE BEGIN 2 */
uartx_write_text(&huart1,"DOBBY 2026\r\n");

//cargo los parametros guardados en flash (o los de defecto si no hay)
 if (Param_init()) uartx_write_text(&huart1,"PARAMETROS: flash\r\n");
 else              uartx_write_text(&huart1,"PARAMETROS: defecto\r\n");
 Param_a_trama(texto);
 uartx_write_text(&huart1,texto);
//PID de linea con los parametros cargados (antes PID_DIR nunca se iniciaba)
 PID_DIR_INIT();
 Param_aplica();

//prueba de la SD: monta, muestra espacio, lee test.txt y escribe dobby.txt
 if (SD_INIT())
 {
   uint32_t total_kb, libre_kb;
   uartx_write_text(&huart1,"SD: montada\r\n");

   if (SD_ESPACIO(&total_kb, &libre_kb))
   {
     sprintf(texto,"SD: total=%lu KB  libre=%lu KB\r\n",(unsigned long)total_kb,(unsigned long)libre_kb);
     uartx_write_text(&huart1,texto);
   }

   if (SD_READ_LINE_N("test.txt", 0))
   {
     uartx_write_text(&huart1,"SD: test.txt -> ");
     uartx_write_text(&huart1,SD_BUFFER);
     uartx_write_text(&huart1,"\r\n");
   }
   else uartx_write_text(&huart1,"SD: no se pudo leer test.txt\r\n");

   if (SD_WRITE_TEXT("dobby.txt", "Hola desde DOBBY 2026\r\n"))
     uartx_write_text(&huart1,"SD: dobby.txt escrito\r\n");
   else
     uartx_write_text(&huart1,"SD: error al escribir\r\n");
 }
 else
 {
   sprintf(texto,"SD: no montada (error FatFS %d)\r\n",(int)fres);
   uartx_write_text(&huart1,texto);
 }
//SI NECEDITA VER BUS  I2C
 //I2C_SCAN(hi2c1);
//enciendo leds ir
//PIN_ON(IR_ON);
  PIN_ON(LEDR1);
  PIN_OFF(LEDR2);
  //inicio motores
 DRV8871_Init();

  //TIMER_INIT();
  //>>>>> CAMBIO: TIMER_INIT se movio despues de MPU6050_Calibra (ver abajo)

delay_Init();

      WS2812_Color(255,255,255);
    WS2812_Manda_Trama();
    HAL_Delay(500);

  Sensores_init();

  //imu
  if (MPU6050_init()==1)  uartx_write_text(&huart1, "IMU OKS\r\n");
    else   uartx_write_text(&huart1, "IMU BAD\r\n");
     MPU6050_Calibra();

  TIMER_INIT();

//calibro sensores ir

   WS2812_Color(0,0,50);
    WS2812_Manda_Trama();

  PIN_ON(LEDS_IR);
  Calibrar_sensores();
  //Manda_Lecturas_filtrada()
  Manda_Limites(); //MANDA MAXIMOS Y MINIMOS

   WS2812_Color(255,0,0);
    WS2812_Manda_Trama();
//inicio los encoders
//           encoder   PPR modo bits
 Encoder_init(&ENCODER1, 7,  2,  16);
 Encoder_init(&ENCODER2, 7,  2,  32);

//inicio las llantas (motor JGA12-N30-10: reductora 10:1, llanta 23 mm)
//          llanta       encoder    reductora  diametro(mm)
 Llanta_init(&LLANTA_IZQ, &ENCODER1, 10.0f,     23.0f);
 Llanta_init(&LLANTA_DER, &ENCODER2, 10.0f,     23.0f);
//separacion entre llantas (mm)
 Robot_init(160.0f);
//PID de velocidad de las llantas (valores de PID.h) + calibracion desde el panel
 Llanta_control_init();
//maquina de estados de la carrera (arranca en REPOSO; corre en el TIM6)
 Carrera_init();
 Pista_mapa_init();
 if (Pista_mapa_leer_flash())
   uartx_write_text(&huart1, "MAPA FLASH: cargado automaticamente al arrancar\r\n");
 else
   uartx_write_text(&huart1, "MAPA FLASH: no hay mapa guardado valido; pulse APRENDER\r\n");

 //MD_Adelante(800);
 //MI_Adelante(800);
//control IR
 IR_init();
 //IR_calibrar(10);   //SOLO para sacar los codigos: imprime 10 y sigue. Luego comentar
 uartRX_it_idle_dma_init( &UARTRX1);
 PIN_BLINK(LED1);
  /* USER CODE END 2 */

  /* Infinite loop */
  /* USER CODE BEGIN WHILE */
//CALIBRACION DEL PID DE VELOCIDAD con el panel (dobby_panel.py, pestaña VELO)
//procedimiento completo en llanta.h
 manda_pid_parametros();   //el panel arranca viendo las constantes actuales
  while(1)
  {
    lee_ir();
    //START / STOP del control IR: los procesa lee_ir con Carrera_run / Carrera_stop

    if (UARTRX1.flag_rx==1)
	  {
	      //copia el comando y rearma la recepcion YA: asi no se pierde lo que llega
	      //mientras se procesa (SD, flash y CALI tardan)
	      char cmd[256];
	      strncpy(cmd, (char*)UARTRX1.trama_rx, sizeof(cmd) - 1);
	      cmd[sizeof(cmd) - 1] = 0;
		  uartRX_DMA_Re_init(&UARTRX1);
	      procesa_rx(cmd); //procedimeinto donde se procesan los datos
	  }

    Aviso_tarea();    //apaga el parpadeo magenta de "llego un comando"
    Tarea_espera();   //robot quieto: posicion, giro y velocidades para el panel
    Carrera_tarea();  //estado de la carrera y telemetria de carrera
    Pista_mapa_vigilar(CARRERA.estado == CARRERA_REPOSO);
    // Proteccion al agotar el buffer: detener, nunca seguir sin registrar.
    if (Pista_mapa_estado() == PISTA_LLENA &&
        CARRERA.estado != CARRERA_REPOSO)
    {
      Carrera_stop();
      uartx_write_text(&huart1, "MAPA: RAM completa, robot detenido\r\n");
      Pista_mapa_estado_uart();
    }
    Prueba_tarea();   //maquina de estados del TEST (solo corre con TEST ON)
    Llanta_tarea();   //graficas del panel + resultados de la identificacion
    //sin HAL_Delay: Llanta_tarea lleva sus propios tiempos

  }

while(1)
  {
  //datos para Teleplot: formato ">nombre:valor\n"
  sprintf(texto,">RPM1:%.0f\n",ENCODER1.rpm);           //rpm motor
  uartx_write_text(&huart1, texto);

  sprintf(texto,">RPM2:%.0f\n",ENCODER2.rpm);
  uartx_write_text(&huart1, texto);

  sprintf(texto,">VIZQ:%.3f\n",LLANTA_IZQ.velocidad);   //m/s
  uartx_write_text(&huart1, texto);

  sprintf(texto,">VDER:%.3f\n",LLANTA_DER.velocidad);
  uartx_write_text(&huart1, texto);

  sprintf(texto,">VROBOT:%.3f\n",ROBOT.velocidad);      //m/s centro del robot
  uartx_write_text(&huart1, texto);

  sprintf(texto,">GIRO:%.2f\n",ROBOT.giro);             //rad/s
  uartx_write_text(&huart1, texto);

  sprintf(texto,">DIST:%.3f\n",ROBOT.distancia);        //m
  uartx_write_text(&huart1, texto);

  HAL_Delay(20);   //~30 muestras por segundo en la grafica

  }
/*while (1)
  {
  	 sprintf(texto,"giro=%.2f\r\n\r\n",giro_z_filtrado);
      uartx_write_text(&huart1, texto);
      HAL_Delay(1000);

  }
*/
while (1)
    {

 //analiza si solo lee o filtra
    Lee_sensores();
   filtra_sensores();
   Normaliza_sensores();
	 	Manda_Normalizados();
 //   filtra_sensores();
  //Manda_Lecturas();
	      HAL_Delay(1000);

    }

  while (1)
  {
    HAL_GPIO_TogglePin(LED_GPIO_Port, LED_Pin);
    //uartx_write_text(&huart1,"OPERANDO\r\n");
    WS2812_Color(0,255,0);
    WS2812_Manda_Trama();
    HAL_Delay(200);
    /* USER CODE END WHILE */

  }
}

void SystemClock_Config(void)
{
  RCC_OscInitTypeDef RCC_OscInitStruct = {0};
  RCC_ClkInitTypeDef RCC_ClkInitStruct = {0};

  /** Configure the main internal regulator output voltage
  */
  __HAL_PWR_VOLTAGESCALING_CONFIG(PWR_REGULATOR_VOLTAGE_SCALE0);

  while(!__HAL_PWR_GET_FLAG(PWR_FLAG_VOSRDY)) {}

  /** Initializes the RCC Oscillators according to the specified parameters
  * in the RCC_OscInitTypeDef structure.
  */
  RCC_OscInitStruct.OscillatorType = RCC_OSCILLATORTYPE_HSE;
  RCC_OscInitStruct.HSEState = RCC_HSE_ON;
  RCC_OscInitStruct.PLL.PLLState = RCC_PLL_ON;
  RCC_OscInitStruct.PLL.PLLSource = RCC_PLL1_SOURCE_HSE;
  RCC_OscInitStruct.PLL.PLLM = 1;
  RCC_OscInitStruct.PLL.PLLN = 62;
  RCC_OscInitStruct.PLL.PLLP = 2;
  RCC_OscInitStruct.PLL.PLLQ = 2;
  RCC_OscInitStruct.PLL.PLLR = 2;
  RCC_OscInitStruct.PLL.PLLRGE = RCC_PLL1_VCIRANGE_3;
  RCC_OscInitStruct.PLL.PLLVCOSEL = RCC_PLL1_VCORANGE_WIDE;
  RCC_OscInitStruct.PLL.PLLFRACN = 4096;
  if (HAL_RCC_OscConfig(&RCC_OscInitStruct) != HAL_OK)
  {
    Error_Handler();
  }

  /** Initializes the CPU, AHB and APB buses clocks
  */
  RCC_ClkInitStruct.ClockType = RCC_CLOCKTYPE_HCLK|RCC_CLOCKTYPE_SYSCLK
                              |RCC_CLOCKTYPE_PCLK1|RCC_CLOCKTYPE_PCLK2
                              |RCC_CLOCKTYPE_PCLK3;
  RCC_ClkInitStruct.SYSCLKSource = RCC_SYSCLKSOURCE_PLLCLK;
  RCC_ClkInitStruct.AHBCLKDivider = RCC_SYSCLK_DIV1;
  RCC_ClkInitStruct.APB1CLKDivider = RCC_HCLK_DIV1;
  RCC_ClkInitStruct.APB2CLKDivider = RCC_HCLK_DIV1;
  RCC_ClkInitStruct.APB3CLKDivider = RCC_HCLK_DIV1;

  if (HAL_RCC_ClockConfig(&RCC_ClkInitStruct, FLASH_LATENCY_5) != HAL_OK)
  {
    Error_Handler();
  }

  /** Configure the programming delay
  */
  __HAL_FLASH_SET_PROGRAM_DELAY(FLASH_PROGRAMMING_DELAY_2);
}

static void MX_ADC1_Init(void)
{

  ADC_ChannelConfTypeDef sConfig = {0};

  /** Common config
  */
  hadc1.Instance = ADC1;
  hadc1.Init.ClockPrescaler = ADC_CLOCK_ASYNC_DIV4;
  hadc1.Init.Resolution = ADC_RESOLUTION_12B;
  hadc1.Init.DataAlign = ADC_DATAALIGN_RIGHT;
  hadc1.Init.ScanConvMode = ADC_SCAN_ENABLE;
  hadc1.Init.EOCSelection = ADC_EOC_SEQ_CONV;
  hadc1.Init.LowPowerAutoWait = DISABLE;
  hadc1.Init.ContinuousConvMode = ENABLE;
  hadc1.Init.NbrOfConversion = 16;
  hadc1.Init.DiscontinuousConvMode = DISABLE;
  hadc1.Init.ExternalTrigConv = ADC_SOFTWARE_START;
  hadc1.Init.ExternalTrigConvEdge = ADC_EXTERNALTRIGCONVEDGE_NONE;
  hadc1.Init.DMAContinuousRequests = ENABLE;
  hadc1.Init.SamplingMode = ADC_SAMPLING_MODE_NORMAL;
  hadc1.Init.Overrun = ADC_OVR_DATA_PRESERVED;
  hadc1.Init.OversamplingMode = DISABLE;
  if (HAL_ADC_Init(&hadc1) != HAL_OK)
  {
    Error_Handler();
  }

  /** Configure Regular Channel
  */
  sConfig.Channel = ADC_CHANNEL_10;
  sConfig.Rank = ADC_REGULAR_RANK_1;
  sConfig.SamplingTime = ADC_SAMPLETIME_247CYCLES_5;
  sConfig.SingleDiff = ADC_SINGLE_ENDED;
  sConfig.OffsetNumber = ADC_OFFSET_NONE;
  sConfig.Offset = 0;
  if (HAL_ADC_ConfigChannel(&hadc1, &sConfig) != HAL_OK)
  {
    Error_Handler();
  }

  /** Configure Regular Channel
  */
  sConfig.Channel = ADC_CHANNEL_11;
  sConfig.Rank = ADC_REGULAR_RANK_2;
  if (HAL_ADC_ConfigChannel(&hadc1, &sConfig) != HAL_OK)
  {
    Error_Handler();
  }

  /** Configure Regular Channel
  */
  sConfig.Channel = ADC_CHANNEL_12;
  sConfig.Rank = ADC_REGULAR_RANK_3;
  sConfig.SamplingTime = ADC_SAMPLETIME_2CYCLES_5;
  if (HAL_ADC_ConfigChannel(&hadc1, &sConfig) != HAL_OK)
  {
    Error_Handler();
  }

  /** Configure Regular Channel
  */
  sConfig.Channel = ADC_CHANNEL_13;
  sConfig.Rank = ADC_REGULAR_RANK_4;
  sConfig.SamplingTime = ADC_SAMPLETIME_247CYCLES_5;
  if (HAL_ADC_ConfigChannel(&hadc1, &sConfig) != HAL_OK)
  {
    Error_Handler();
  }

  /** Configure Regular Channel
  */
  sConfig.Channel = ADC_CHANNEL_0;
  sConfig.Rank = ADC_REGULAR_RANK_5;
  if (HAL_ADC_ConfigChannel(&hadc1, &sConfig) != HAL_OK)
  {
    Error_Handler();
  }

  /** Configure Regular Channel
  */
  sConfig.Channel = ADC_CHANNEL_1;
  sConfig.Rank = ADC_REGULAR_RANK_6;
  if (HAL_ADC_ConfigChannel(&hadc1, &sConfig) != HAL_OK)
  {
    Error_Handler();
  }

  /** Configure Regular Channel
  */
  sConfig.Channel = ADC_CHANNEL_15;
  sConfig.Rank = ADC_REGULAR_RANK_7;
  if (HAL_ADC_ConfigChannel(&hadc1, &sConfig) != HAL_OK)
  {
    Error_Handler();
  }

  /** Configure Regular Channel
  */
  sConfig.Channel = ADC_CHANNEL_14;
  sConfig.Rank = ADC_REGULAR_RANK_8;
  if (HAL_ADC_ConfigChannel(&hadc1, &sConfig) != HAL_OK)
  {
    Error_Handler();
  }

  /** Configure Regular Channel
  */
  sConfig.Channel = ADC_CHANNEL_18;
  sConfig.Rank = ADC_REGULAR_RANK_9;
  if (HAL_ADC_ConfigChannel(&hadc1, &sConfig) != HAL_OK)
  {
    Error_Handler();
  }

  /** Configure Regular Channel
  */
  sConfig.Channel = ADC_CHANNEL_19;
  sConfig.Rank = ADC_REGULAR_RANK_10;
  if (HAL_ADC_ConfigChannel(&hadc1, &sConfig) != HAL_OK)
  {
    Error_Handler();
  }

  /** Configure Regular Channel
  */
  sConfig.Channel = ADC_CHANNEL_3;
  sConfig.Rank = ADC_REGULAR_RANK_11;
  if (HAL_ADC_ConfigChannel(&hadc1, &sConfig) != HAL_OK)
  {
    Error_Handler();
  }

  /** Configure Regular Channel
  */
  sConfig.Channel = ADC_CHANNEL_7;
  sConfig.Rank = ADC_REGULAR_RANK_12;
  if (HAL_ADC_ConfigChannel(&hadc1, &sConfig) != HAL_OK)
  {
    Error_Handler();
  }

  /** Configure Regular Channel
  */
  sConfig.Channel = ADC_CHANNEL_4;
  sConfig.Rank = ADC_REGULAR_RANK_13;
  if (HAL_ADC_ConfigChannel(&hadc1, &sConfig) != HAL_OK)
  {
    Error_Handler();
  }

  /** Configure Regular Channel
  */
  sConfig.Channel = ADC_CHANNEL_8;
  sConfig.Rank = ADC_REGULAR_RANK_14;
  if (HAL_ADC_ConfigChannel(&hadc1, &sConfig) != HAL_OK)
  {
    Error_Handler();
  }

  /** Configure Regular Channel
  */
  sConfig.Channel = ADC_CHANNEL_9;
  sConfig.Rank = ADC_REGULAR_RANK_15;
  if (HAL_ADC_ConfigChannel(&hadc1, &sConfig) != HAL_OK)
  {
    Error_Handler();
  }

  /** Configure Regular Channel
  */
  sConfig.Channel = ADC_CHANNEL_5;
  sConfig.Rank = ADC_REGULAR_RANK_16;
  if (HAL_ADC_ConfigChannel(&hadc1, &sConfig) != HAL_OK)
  {
    Error_Handler();
  }

}

static void MX_GPDMA1_Init(void)
{

  /* Peripheral clock enable */
  __HAL_RCC_GPDMA1_CLK_ENABLE();

  /* GPDMA1 interrupt Init */
    HAL_NVIC_SetPriority(GPDMA1_Channel0_IRQn, 0, 0);
    HAL_NVIC_EnableIRQ(GPDMA1_Channel0_IRQn);
    HAL_NVIC_SetPriority(GPDMA1_Channel1_IRQn, 0, 0);
    HAL_NVIC_EnableIRQ(GPDMA1_Channel1_IRQn);

}

static void MX_GPDMA2_Init(void)
{

  /* Peripheral clock enable */
  __HAL_RCC_GPDMA2_CLK_ENABLE();

  /* GPDMA2 interrupt Init */
    HAL_NVIC_SetPriority(GPDMA2_Channel0_IRQn, 0, 0);
    HAL_NVIC_EnableIRQ(GPDMA2_Channel0_IRQn);

}

static void MX_I2C1_Init(void)
{

  hi2c1.Instance = I2C1;
  hi2c1.Init.Timing = 0x10C043E5;
  hi2c1.Init.OwnAddress1 = 0;
  hi2c1.Init.AddressingMode = I2C_ADDRESSINGMODE_7BIT;
  hi2c1.Init.DualAddressMode = I2C_DUALADDRESS_DISABLE;
  hi2c1.Init.OwnAddress2 = 0;
  hi2c1.Init.OwnAddress2Masks = I2C_OA2_NOMASK;
  hi2c1.Init.GeneralCallMode = I2C_GENERALCALL_DISABLE;
  hi2c1.Init.NoStretchMode = I2C_NOSTRETCH_DISABLE;
  if (HAL_I2C_Init(&hi2c1) != HAL_OK)
  {
    Error_Handler();
  }

  /** Configure Analogue filter
  */
  if (HAL_I2CEx_ConfigAnalogFilter(&hi2c1, I2C_ANALOGFILTER_ENABLE) != HAL_OK)
  {
    Error_Handler();
  }

  /** Configure Digital filter
  */
  if (HAL_I2CEx_ConfigDigitalFilter(&hi2c1, 0) != HAL_OK)
  {
    Error_Handler();
  }

}

static void MX_ICACHE_Init(void)
{

  /** Enable instruction cache in 1-way (direct mapped cache)
  */
  if (HAL_ICACHE_ConfigAssociativityMode(ICACHE_1WAY) != HAL_OK)
  {
    Error_Handler();
  }
  if (HAL_ICACHE_Enable() != HAL_OK)
  {
    Error_Handler();
  }

}

static void MX_SDMMC1_SD_Init(void)
{

  hsd1.Instance = SDMMC1;
  hsd1.Init.ClockEdge = SDMMC_CLOCK_EDGE_RISING;
  hsd1.Init.ClockPowerSave = SDMMC_CLOCK_POWER_SAVE_DISABLE;
  hsd1.Init.BusWide = SDMMC_BUS_WIDE_4B;
  hsd1.Init.HardwareFlowControl = SDMMC_HARDWARE_FLOW_CONTROL_DISABLE;
  hsd1.Init.ClockDiv = 8;
  if (HAL_SD_Init(&hsd1) != HAL_OK)
  {
    Error_Handler();
  }

}

static void MX_TIM1_Init(void)
{

  TIM_Encoder_InitTypeDef sConfig = {0};
  TIM_MasterConfigTypeDef sMasterConfig = {0};

  htim1.Instance = TIM1;
  htim1.Init.Prescaler = 0;
  htim1.Init.CounterMode = TIM_COUNTERMODE_UP;
  htim1.Init.Period = 65535;
  htim1.Init.ClockDivision = TIM_CLOCKDIVISION_DIV1;
  htim1.Init.RepetitionCounter = 0;
  htim1.Init.AutoReloadPreload = TIM_AUTORELOAD_PRELOAD_DISABLE;
  sConfig.EncoderMode = TIM_ENCODERMODE_TI1;
  sConfig.IC1Polarity = TIM_ICPOLARITY_RISING;
  sConfig.IC1Selection = TIM_ICSELECTION_DIRECTTI;
  sConfig.IC1Prescaler = TIM_ICPSC_DIV1;
  sConfig.IC1Filter = 0;
  sConfig.IC2Polarity = TIM_ICPOLARITY_RISING;
  sConfig.IC2Selection = TIM_ICSELECTION_DIRECTTI;
  sConfig.IC2Prescaler = TIM_ICPSC_DIV1;
  sConfig.IC2Filter = 0;
  if (HAL_TIM_Encoder_Init(&htim1, &sConfig) != HAL_OK)
  {
    Error_Handler();
  }
  sMasterConfig.MasterOutputTrigger = TIM_TRGO_RESET;
  sMasterConfig.MasterOutputTrigger2 = TIM_TRGO2_RESET;
  sMasterConfig.MasterSlaveMode = TIM_MASTERSLAVEMODE_DISABLE;
  if (HAL_TIMEx_MasterConfigSynchronization(&htim1, &sMasterConfig) != HAL_OK)
  {
    Error_Handler();
  }

}

static void MX_TIM2_Init(void)
{

  TIM_Encoder_InitTypeDef sConfig = {0};
  TIM_MasterConfigTypeDef sMasterConfig = {0};

  htim2.Instance = TIM2;
  htim2.Init.Prescaler = 0;
  htim2.Init.CounterMode = TIM_COUNTERMODE_UP;
  htim2.Init.Period = 4294967295;
  htim2.Init.ClockDivision = TIM_CLOCKDIVISION_DIV1;
  htim2.Init.AutoReloadPreload = TIM_AUTORELOAD_PRELOAD_DISABLE;
  sConfig.EncoderMode = TIM_ENCODERMODE_TI1;
  sConfig.IC1Polarity = TIM_ICPOLARITY_RISING;
  sConfig.IC1Selection = TIM_ICSELECTION_DIRECTTI;
  sConfig.IC1Prescaler = TIM_ICPSC_DIV1;
  sConfig.IC1Filter = 0;
  sConfig.IC2Polarity = TIM_ICPOLARITY_RISING;
  sConfig.IC2Selection = TIM_ICSELECTION_DIRECTTI;
  sConfig.IC2Prescaler = TIM_ICPSC_DIV1;
  sConfig.IC2Filter = 0;
  if (HAL_TIM_Encoder_Init(&htim2, &sConfig) != HAL_OK)
  {
    Error_Handler();
  }
  sMasterConfig.MasterOutputTrigger = TIM_TRGO_RESET;
  sMasterConfig.MasterSlaveMode = TIM_MASTERSLAVEMODE_DISABLE;
  if (HAL_TIMEx_MasterConfigSynchronization(&htim2, &sMasterConfig) != HAL_OK)
  {
    Error_Handler();
  }

}

static void MX_TIM3_Init(void)
{

  TIM_ClockConfigTypeDef sClockSourceConfig = {0};
  TIM_MasterConfigTypeDef sMasterConfig = {0};
  TIM_OC_InitTypeDef sConfigOC = {0};

  htim3.Instance = TIM3;
  htim3.Init.Prescaler = 0;
  htim3.Init.CounterMode = TIM_COUNTERMODE_UP;
  htim3.Init.Period = 312;
  htim3.Init.ClockDivision = TIM_CLOCKDIVISION_DIV1;
  htim3.Init.AutoReloadPreload = TIM_AUTORELOAD_PRELOAD_ENABLE;
  if (HAL_TIM_Base_Init(&htim3) != HAL_OK)
  {
    Error_Handler();
  }
  sClockSourceConfig.ClockSource = TIM_CLOCKSOURCE_INTERNAL;
  if (HAL_TIM_ConfigClockSource(&htim3, &sClockSourceConfig) != HAL_OK)
  {
    Error_Handler();
  }
  if (HAL_TIM_PWM_Init(&htim3) != HAL_OK)
  {
    Error_Handler();
  }
  sMasterConfig.MasterOutputTrigger = TIM_TRGO_RESET;
  sMasterConfig.MasterSlaveMode = TIM_MASTERSLAVEMODE_DISABLE;
  if (HAL_TIMEx_MasterConfigSynchronization(&htim3, &sMasterConfig) != HAL_OK)
  {
    Error_Handler();
  }
  sConfigOC.OCMode = TIM_OCMODE_PWM1;
  sConfigOC.Pulse = 99;
  sConfigOC.OCPolarity = TIM_OCPOLARITY_HIGH;
  sConfigOC.OCFastMode = TIM_OCFAST_DISABLE;
  if (HAL_TIM_PWM_ConfigChannel(&htim3, &sConfigOC, TIM_CHANNEL_1) != HAL_OK)
  {
    Error_Handler();
  }
  HAL_TIM_MspPostInit(&htim3);

}

static void MX_TIM4_Init(void)
{

  TIM_ClockConfigTypeDef sClockSourceConfig = {0};
  TIM_MasterConfigTypeDef sMasterConfig = {0};
  TIM_OC_InitTypeDef sConfigOC = {0};

  htim4.Instance = TIM4;
  htim4.Init.Prescaler = 10-1;
  htim4.Init.CounterMode = TIM_COUNTERMODE_UP;
  htim4.Init.Period = 1000;
  htim4.Init.ClockDivision = TIM_CLOCKDIVISION_DIV1;
  htim4.Init.AutoReloadPreload = TIM_AUTORELOAD_PRELOAD_ENABLE;
  if (HAL_TIM_Base_Init(&htim4) != HAL_OK)
  {
    Error_Handler();
  }
  sClockSourceConfig.ClockSource = TIM_CLOCKSOURCE_INTERNAL;
  if (HAL_TIM_ConfigClockSource(&htim4, &sClockSourceConfig) != HAL_OK)
  {
    Error_Handler();
  }
  if (HAL_TIM_PWM_Init(&htim4) != HAL_OK)
  {
    Error_Handler();
  }
  sMasterConfig.MasterOutputTrigger = TIM_TRGO_RESET;
  sMasterConfig.MasterSlaveMode = TIM_MASTERSLAVEMODE_DISABLE;
  if (HAL_TIMEx_MasterConfigSynchronization(&htim4, &sMasterConfig) != HAL_OK)
  {
    Error_Handler();
  }
  sConfigOC.OCMode = TIM_OCMODE_PWM1;
  sConfigOC.Pulse = 0;
  sConfigOC.OCPolarity = TIM_OCPOLARITY_HIGH;
  sConfigOC.OCFastMode = TIM_OCFAST_DISABLE;
  if (HAL_TIM_PWM_ConfigChannel(&htim4, &sConfigOC, TIM_CHANNEL_1) != HAL_OK)
  {
    Error_Handler();
  }
  if (HAL_TIM_PWM_ConfigChannel(&htim4, &sConfigOC, TIM_CHANNEL_2) != HAL_OK)
  {
    Error_Handler();
  }
  if (HAL_TIM_PWM_ConfigChannel(&htim4, &sConfigOC, TIM_CHANNEL_3) != HAL_OK)
  {
    Error_Handler();
  }
  if (HAL_TIM_PWM_ConfigChannel(&htim4, &sConfigOC, TIM_CHANNEL_4) != HAL_OK)
  {
    Error_Handler();
  }
  HAL_TIM_MspPostInit(&htim4);

}

static void MX_TIM6_Init(void)
{

  TIM_MasterConfigTypeDef sMasterConfig = {0};

  htim6.Instance = TIM6;
  htim6.Init.Prescaler = 2500-1;
  htim6.Init.CounterMode = TIM_COUNTERMODE_UP;
  htim6.Init.Period = 499;
  htim6.Init.AutoReloadPreload = TIM_AUTORELOAD_PRELOAD_ENABLE;
  if (HAL_TIM_Base_Init(&htim6) != HAL_OK)
  {
    Error_Handler();
  }
  sMasterConfig.MasterOutputTrigger = TIM_TRGO_RESET;
  sMasterConfig.MasterSlaveMode = TIM_MASTERSLAVEMODE_DISABLE;
  if (HAL_TIMEx_MasterConfigSynchronization(&htim6, &sMasterConfig) != HAL_OK)
  {
    Error_Handler();
  }

}

static void MX_TIM7_Init(void)
{

  TIM_MasterConfigTypeDef sMasterConfig = {0};

  htim7.Instance = TIM7;
  htim7.Init.Prescaler = 250-1;
  htim7.Init.CounterMode = TIM_COUNTERMODE_UP;
  htim7.Init.Period = 8000;
  htim7.Init.AutoReloadPreload = TIM_AUTORELOAD_PRELOAD_ENABLE;
  if (HAL_TIM_Base_Init(&htim7) != HAL_OK)
  {
    Error_Handler();
  }
  sMasterConfig.MasterOutputTrigger = TIM_TRGO_RESET;
  sMasterConfig.MasterSlaveMode = TIM_MASTERSLAVEMODE_DISABLE;
  if (HAL_TIMEx_MasterConfigSynchronization(&htim7, &sMasterConfig) != HAL_OK)
  {
    Error_Handler();
  }

}

static void MX_USART1_UART_Init(void)
{

  huart1.Instance = USART1;
  huart1.Init.BaudRate = 115200;
  huart1.Init.WordLength = UART_WORDLENGTH_8B;
  huart1.Init.StopBits = UART_STOPBITS_1;
  huart1.Init.Parity = UART_PARITY_NONE;
  huart1.Init.Mode = UART_MODE_TX_RX;
  huart1.Init.HwFlowCtl = UART_HWCONTROL_NONE;
  huart1.Init.OverSampling = UART_OVERSAMPLING_16;
  huart1.Init.OneBitSampling = UART_ONE_BIT_SAMPLE_DISABLE;
  huart1.Init.ClockPrescaler = UART_PRESCALER_DIV1;
  huart1.AdvancedInit.AdvFeatureInit = UART_ADVFEATURE_NO_INIT;
  if (HAL_UART_Init(&huart1) != HAL_OK)
  {
    Error_Handler();
  }
  if (HAL_UARTEx_SetTxFifoThreshold(&huart1, UART_TXFIFO_THRESHOLD_1_8) != HAL_OK)
  {
    Error_Handler();
  }
  if (HAL_UARTEx_SetRxFifoThreshold(&huart1, UART_RXFIFO_THRESHOLD_1_8) != HAL_OK)
  {
    Error_Handler();
  }
  if (HAL_UARTEx_DisableFifoMode(&huart1) != HAL_OK)
  {
    Error_Handler();
  }

}

static void MX_USART3_UART_Init(void)
{

  huart3.Instance = USART3;
  huart3.Init.BaudRate = 115200;
  huart3.Init.WordLength = UART_WORDLENGTH_8B;
  huart3.Init.StopBits = UART_STOPBITS_1;
  huart3.Init.Parity = UART_PARITY_NONE;
  huart3.Init.Mode = UART_MODE_TX_RX;
  huart3.Init.HwFlowCtl = UART_HWCONTROL_NONE;
  huart3.Init.OverSampling = UART_OVERSAMPLING_16;
  huart3.Init.OneBitSampling = UART_ONE_BIT_SAMPLE_DISABLE;
  huart3.Init.ClockPrescaler = UART_PRESCALER_DIV1;
  huart3.AdvancedInit.AdvFeatureInit = UART_ADVFEATURE_NO_INIT;
  if (HAL_UART_Init(&huart3) != HAL_OK)
  {
    Error_Handler();
  }
  if (HAL_UARTEx_SetTxFifoThreshold(&huart3, UART_TXFIFO_THRESHOLD_1_8) != HAL_OK)
  {
    Error_Handler();
  }
  if (HAL_UARTEx_SetRxFifoThreshold(&huart3, UART_RXFIFO_THRESHOLD_1_8) != HAL_OK)
  {
    Error_Handler();
  }
  if (HAL_UARTEx_DisableFifoMode(&huart3) != HAL_OK)
  {
    Error_Handler();
  }

}

static void MX_GPIO_Init(void)
{
  GPIO_InitTypeDef GPIO_InitStruct = {0};

  /* GPIO Ports Clock Enable */
  __HAL_RCC_GPIOC_CLK_ENABLE();
  __HAL_RCC_GPIOH_CLK_ENABLE();
  __HAL_RCC_GPIOA_CLK_ENABLE();
  __HAL_RCC_GPIOB_CLK_ENABLE();
  __HAL_RCC_GPIOE_CLK_ENABLE();
  __HAL_RCC_GPIOD_CLK_ENABLE();

  /*Configure GPIO pin Output Level */
  HAL_GPIO_WritePin(SW_IN_GPIO_Port, SW_IN_Pin, GPIO_PIN_RESET);

  /*Configure GPIO pin Output Level */
  HAL_GPIO_WritePin(GPIOB, LED_Pin|LEDS_IR_Pin, GPIO_PIN_RESET);

  /*Configure GPIO pin Output Level */
  HAL_GPIO_WritePin(GPIOD, LED1_Pin|LEDR1_Pin|LEDR2_Pin, GPIO_PIN_RESET);

  /*Configure GPIO pin : SW_IN_Pin */
  GPIO_InitStruct.Pin = SW_IN_Pin;
  GPIO_InitStruct.Mode = GPIO_MODE_OUTPUT_PP;
  GPIO_InitStruct.Pull = GPIO_NOPULL;
  GPIO_InitStruct.Speed = GPIO_SPEED_FREQ_LOW;
  HAL_GPIO_Init(SW_IN_GPIO_Port, &GPIO_InitStruct);

  /*Configure GPIO pins : LED_Pin LEDS_IR_Pin */
  GPIO_InitStruct.Pin = LED_Pin|LEDS_IR_Pin;
  GPIO_InitStruct.Mode = GPIO_MODE_OUTPUT_PP;
  GPIO_InitStruct.Pull = GPIO_NOPULL;
  GPIO_InitStruct.Speed = GPIO_SPEED_FREQ_LOW;
  HAL_GPIO_Init(GPIOB, &GPIO_InitStruct);

  /*Configure GPIO pins : LED1_Pin LEDR1_Pin LEDR2_Pin */
  GPIO_InitStruct.Pin = LED1_Pin|LEDR1_Pin|LEDR2_Pin;
  GPIO_InitStruct.Mode = GPIO_MODE_OUTPUT_PP;
  GPIO_InitStruct.Pull = GPIO_NOPULL;
  GPIO_InitStruct.Speed = GPIO_SPEED_FREQ_LOW;
  HAL_GPIO_Init(GPIOD, &GPIO_InitStruct);

  /*Configure GPIO pin : SD_DET_Pin */
  GPIO_InitStruct.Pin = SD_DET_Pin;
  GPIO_InitStruct.Mode = GPIO_MODE_INPUT;
  GPIO_InitStruct.Pull = GPIO_PULLUP;
  HAL_GPIO_Init(SD_DET_GPIO_Port, &GPIO_InitStruct);

  /*Configure GPIO pin : STOP_Pin */
  GPIO_InitStruct.Pin = STOP_Pin;
  GPIO_InitStruct.Mode = GPIO_MODE_INPUT;
  GPIO_InitStruct.Pull = GPIO_NOPULL;
  HAL_GPIO_Init(STOP_GPIO_Port, &GPIO_InitStruct);

  /*Configure GPIO pin : IR_in_Pin */
  GPIO_InitStruct.Pin = IR_in_Pin;
  GPIO_InitStruct.Mode = GPIO_MODE_IT_RISING;
  GPIO_InitStruct.Pull = GPIO_PULLUP;
  HAL_GPIO_Init(IR_in_GPIO_Port, &GPIO_InitStruct);

  /* EXTI interrupt init*/
  HAL_NVIC_SetPriority(EXTI9_IRQn, 0, 0);
  HAL_NVIC_EnableIRQ(EXTI9_IRQn);

}

 /* MPU Configuration */

void MPU_Config(void)
{
  MPU_Region_InitTypeDef MPU_InitStruct = {0};
  MPU_Attributes_InitTypeDef MPU_AttributesInit = {0};

  /* Disables the MPU */
  HAL_MPU_Disable();

  /** Initializes and configures the Region 0 and the memory to be protected
  */
  MPU_InitStruct.Enable = MPU_REGION_ENABLE;
  MPU_InitStruct.Number = MPU_REGION_NUMBER0;
  MPU_InitStruct.BaseAddress = 0x08FFF000;
  MPU_InitStruct.LimitAddress = 0x08FFFFFF;
  MPU_InitStruct.AttributesIndex = MPU_ATTRIBUTES_NUMBER0;
  MPU_InitStruct.AccessPermission = MPU_REGION_ALL_RO;
  MPU_InitStruct.DisableExec = MPU_INSTRUCTION_ACCESS_DISABLE;
  MPU_InitStruct.IsShareable = MPU_ACCESS_NOT_SHAREABLE;

  HAL_MPU_ConfigRegion(&MPU_InitStruct);

  /** Initializes and configures the Attribute 0 and the memory to be protected
  */
  MPU_AttributesInit.Number = MPU_ATTRIBUTES_NUMBER0;
  MPU_AttributesInit.Attributes = INNER_OUTER(MPU_NOT_CACHEABLE);

  HAL_MPU_ConfigMemoryAttributes(&MPU_AttributesInit);
  /* Enables the MPU */
  HAL_MPU_Enable(MPU_PRIVILEGED_DEFAULT);

}

void Error_Handler(void)
{
  __disable_irq();
  while (1)
  {
  }
}
